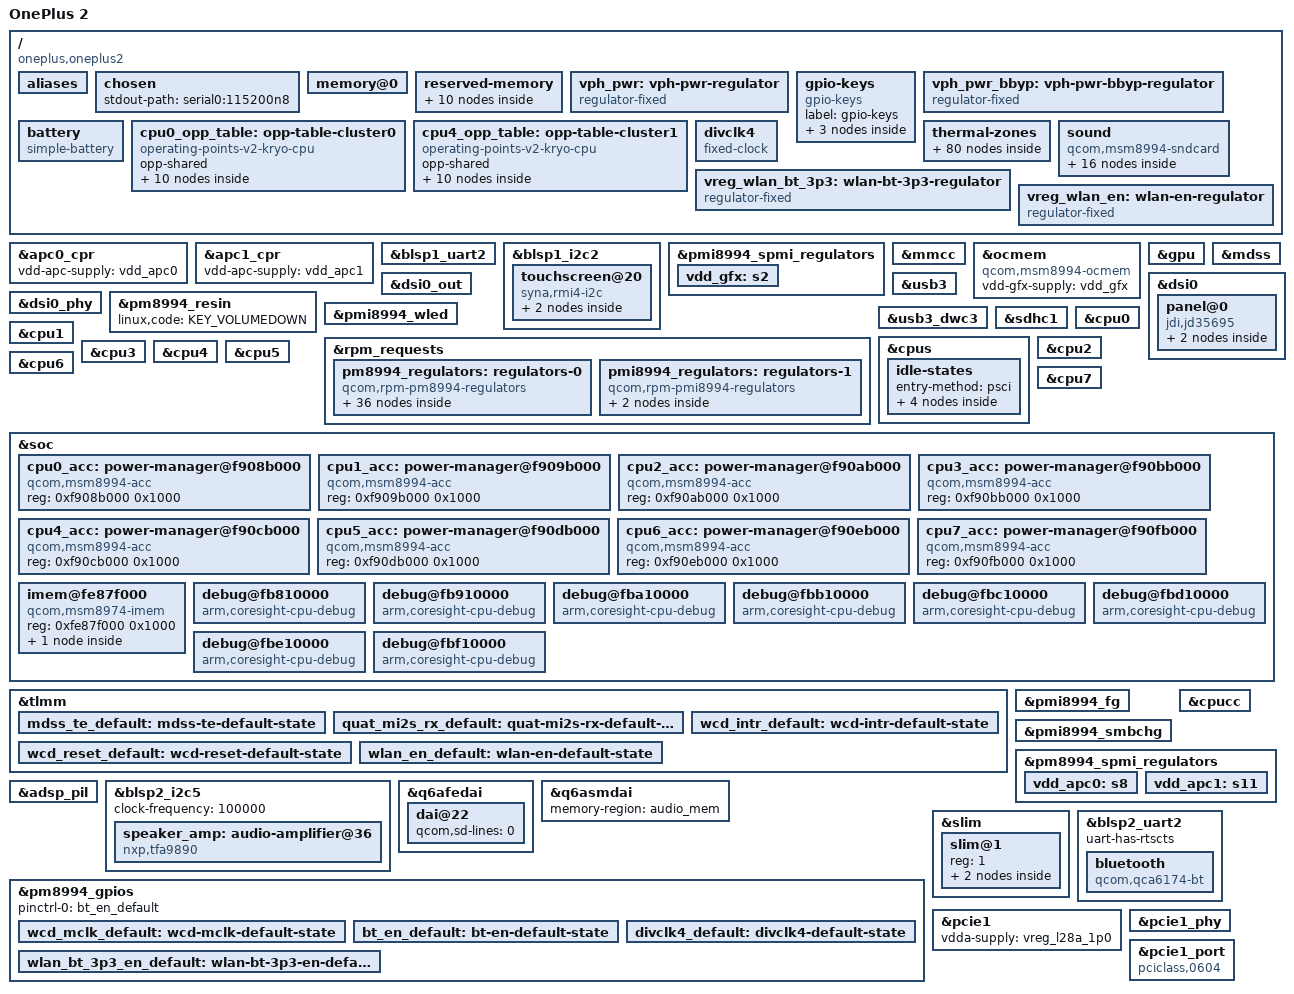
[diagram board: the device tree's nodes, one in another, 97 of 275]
// SPDX-License-Identifier: BSD-3-Clause
/*
 * OnePlus 2 (oneplus2, project 14049), MSM8994 v2.1.
 *
 * The memory map, regulator voltages and peripherals follow the stock
 * OxygenOS 3.10 device tree (board-id 14) and what the stock kernel logs on
 * the phone.
 */

/dts-v1/;

#include "msm8994.dtsi"
#include "pm8994.dtsi"
#include "pmi8994.dtsi"
#include <dt-bindings/gpio/gpio.h>
#include <dt-bindings/input/gpio-keys.h>
#include <dt-bindings/input/input.h>
#include <dt-bindings/interrupt-controller/irq.h>
#include <dt-bindings/pinctrl/qcom,pmic-gpio.h>
#include <dt-bindings/thermal/thermal.h>

/* placed as the stock kernel places them */
/delete-node/ &audio_mem;
/delete-node/ &adsp_mem;

/ {
	model = "OnePlus 2";
	compatible = "oneplus,oneplus2", "qcom,msm8994";
	chassis-type = "handset";

	/* the stock LK picks its DTB by these */
	qcom,msm-id = <207 0x20001>;
	qcom,board-id = <8 0 14049 14>;

	aliases {
		serial0 = &blsp1_uart2;
		serial1 = &blsp2_uart2;
		mmc0 = &sdhc1;
	};

	chosen {
		stdout-path = "serial0:115200n8";
	};

	/* LK rewrites the banks from SMEM; these are the 4 GB phone's */
	memory@0 {
		device_type = "memory";
		reg = <0 0x00000000 0 0x80000000>,
		      <0 0x80000000 0 0x78000000>;
	};

	reserved-memory {
		/*
		 * The TZ has no PSCI: lk2nd starts the secondary CPUs and parks
		 * them here (spin-table), in RAM no bootloader loads into.
		 */
		spin-table@6100000 {
			reg = <0 0x06100000 0 0x1000>;
			no-map;
		};

		nvbackup_mem: memory@6200000 {
			reg = <0 0x06200000 0 0x100000>;
			no-map;
		};

		/* holds SMEM (0x6a00000) and the hypervisor (0x6c00000) */
		memory_hole: memory@6300000 {
			reg = <0 0x06300000 0 0x700000>;
			no-map;
		};

		tzapp_mem: memory@e900000 {
			reg = <0 0x0e900000 0 0x1900000>;
			no-map;
		};

		/* the layout the OnePlus 2 kernels and TWRP use, so each reads the other */
		ramoops@ac000000 {
			compatible = "ramoops";
			reg = <0 0xac000000 0 0x100000>;
			record-size = <0x1000>;
			console-size = <0x40000>;
			ftrace-size = <0x1000>;
			pmsg-size = <0x1000>;
		};

		param_mem: memory@ac200000 {
			reg = <0 0xac200000 0 0x100000>;
			no-map;
		};

		mtp_mem: memory@ac400000 {
			reg = <0 0xac400000 0 0x100000>;
			no-map;
		};

		/* the ADSP's audio buffers (q6asm), shared with it through the TZ */
		audio_mem: memory@df400000 {
			compatible = "shared-dma-pool";
			reg = <0 0xdf400000 0 0x800000>;
			no-map;
		};

		qseecom_mem: memory@dfc00000 {
			reg = <0 0xdfc00000 0 0x1800000>;
			no-map;
		};

		adsp_mem: memory@e1400000 {
			reg = <0 0xe1400000 0 0x3f00000>;
			no-map;
		};
	};

	vph_pwr: vph-pwr-regulator {
		compatible = "regulator-fixed";
		regulator-name = "vph_pwr";
		regulator-min-microvolt = <3700000>;
		regulator-max-microvolt = <3700000>;
		regulator-always-on;
		regulator-boot-on;
	};

	gpio-keys {
		compatible = "gpio-keys";
		label = "gpio-keys";

		key-volume-up {
			label = "volume_up";
			gpios = <&pm8994_gpios 3 GPIO_ACTIVE_LOW>;
			linux,input-type = <EV_KEY>;
			linux,code = <KEY_VOLUMEUP>;
			debounce-interval = <15>;
		};

		key-volume-down {
			label = "volume_down";
			gpios = <&pm8994_gpios 2 GPIO_ACTIVE_LOW>;
			linux,input-type = <EV_KEY>;
			linux,code = <KEY_VOLUMEDOWN>;
			debounce-interval = <15>;
		};

		event-hall-sensor {
			label = "hall_sensor";
			gpios = <&tlmm 75 GPIO_ACTIVE_LOW>;
			linux,input-type = <EV_SW>;
			linux,code = <SW_LID>;
			debounce-interval = <15>;
			wakeup-source;
		};
	};

	vph_pwr_bbyp: vph-pwr-bbyp-regulator {
		compatible = "regulator-fixed";
		regulator-name = "vph_pwr_bbyp";
		regulator-min-microvolt = <3700000>;
		regulator-max-microvolt = <3700000>;
		regulator-always-on;
		regulator-boot-on;
	};
};

&apc0_cpr {
	vdd-apc-supply = <&vdd_apc0>;
	status = "okay";
};

&apc1_cpr {
	vdd-apc-supply = <&vdd_apc1>;
	status = "okay";
};

&blsp1_uart2 {
	status = "okay";
};

&blsp1_i2c2 {
	status = "okay";

	/* Synaptics S3320, RMI4 */
	touchscreen@20 {
		compatible = "syna,rmi4-i2c";
		reg = <0x20>;
		#address-cells = <1>;
		#size-cells = <0>;

		interrupts-extended = <&tlmm 96 IRQ_TYPE_LEVEL_LOW>;
		reset-gpios = <&tlmm 31 GPIO_ACTIVE_LOW>;
		vdd-supply = <&vreg_l22a_3p0>;

		syna,startup-delay-ms = <100>;

		rmi4-f01@1 {
			reg = <0x01>;
			syna,nosleep-mode = <2>;	/* on: no doze, quick taps register */
		};

		rmi4-f12@12 {
			reg = <0x12>;
			syna,sensor-type = <1>;
		};
	};
};

&pmi8994_spmi_regulators {
	/*
	 * S2 (ganged with S3) is VDD_GFX, the GX GDSC's parent supply in the
	 * stock device tree (pmi8994_s2_corner).  Without it the GPU's GX
	 * clocks never turn on and its IOMMU hangs the bus at probe.
	 */
	vdd_gfx: s2 {
		regulator-min-microvolt = <980000>;
		regulator-max-microvolt = <980000>;
	};
};

&mmcc {
	vdd-gfx-supply = <&vdd_gfx>;
	/*
	 * The MMSS clocks and PLLs run on VDDCX: the stock clock driver
	 * votes CX corners for them (vdd_dig-supply = pm8994_s1_corner).
	 * Without a vote MMPLL1 can fail to lock and MDP probe hangs.
	 */
	power-domains = <&rpmpd MSM8994_VDDCX>;
	required-opps = <&rpmpd_opp_nom>;
};

&ocmem {
	compatible = "qcom,msm8994-ocmem";
	vdd-gfx-supply = <&vdd_gfx>;
};

&gpu {
	status = "okay";
};

&mdss {
	status = "okay";
};

&dsi0 {
	#address-cells = <1>;
	#size-cells = <0>;

	vdda-supply = <&vreg_l2a_1p25>;
	vddio-supply = <&vreg_l14a_1p8>;
	status = "okay";

	panel@0 {
		compatible = "jdi,jd35695";
		reg = <0>;

		backlight = <&pmi8994_wled>;
		vddio-supply = <&vreg_l14a_1p8>;
		reset-gpios = <&tlmm 78 GPIO_ACTIVE_LOW>;

		pinctrl-0 = <&mdss_te_default>;
		pinctrl-names = "default";

		port {
			panel_in: endpoint {
				remote-endpoint = <&dsi0_out>;
			};
		};
	};
};

&dsi0_out {
	remote-endpoint = <&panel_in>;
	data-lanes = <0 1 2 3>;
};

&dsi0_phy {
	/* The stock panel timings: without them the last line is lost */
	qcom,t-clk-post = <0x20>;
	qcom,t-clk-pre = <0x3e>;
	status = "okay";
};

&pm8994_resin {
	linux,code = <KEY_VOLUMEDOWN>;
	status = "okay";
};

&pmi8994_wled {
	qcom,enabled-strings = <0 1>;
	qcom,current-limit-microamp = <20000>;
	qcom,ovp-millivolt = <29500>;
	qcom,switching-freq = <800>;
	qcom,cabc;
	status = "okay";
};

&rpm_requests {
	pm8994_regulators: regulators-0 {
		compatible = "qcom,rpm-pm8994-regulators";

		vdd_s1-supply = <&vph_pwr>;
		vdd_s2-supply = <&vph_pwr>;
		vdd_s3-supply = <&vph_pwr>;
		vdd_s4-supply = <&vph_pwr>;
		vdd_s5-supply = <&vph_pwr>;
		vdd_s6-supply = <&vph_pwr>;
		vdd_s7-supply = <&vph_pwr>;
		vdd_s8-supply = <&vph_pwr>;
		vdd_s9-supply = <&vph_pwr>;
		vdd_s10-supply = <&vph_pwr>;
		vdd_s11-supply = <&vph_pwr>;
		vdd_s12-supply = <&vph_pwr>;
		vdd_l1-supply = <&vreg_s1b_1p025>;
		vdd_l2_l26_l28-supply = <&vreg_s3a_1p3>;
		vdd_l3_l11-supply = <&vreg_s3a_1p3>;
		vdd_l4_l27_l31-supply = <&vreg_s3a_1p3>;
		vdd_l5_l7-supply = <&vreg_s5a_2p15>;
		vdd_l6_l12_l32-supply = <&vreg_s5a_2p15>;
		vdd_l8_l16_l30-supply = <&vph_pwr>;
		vdd_l9_l10_l18_l22-supply = <&vph_pwr_bbyp>;
		vdd_l13_l19_l23_l24-supply = <&vph_pwr_bbyp>;
		vdd_l14_l15-supply = <&vreg_s5a_2p15>;
		vdd_l17_l29-supply = <&vph_pwr_bbyp>;
		vdd_l20_l21-supply = <&vph_pwr_bbyp>;
		vdd_l25-supply = <&vreg_s5a_2p15>;
		vdd_lvs1_2-supply = <&vreg_s4a_1p8>;

		/* S1, S2, S6 and S12 are RPMPD's; S8-S11 the CPUs' (SPMI) */

		vreg_s3a_1p3: s3 {
			regulator-min-microvolt = <1300000>;
			regulator-max-microvolt = <1300000>;
		};

		vreg_s4a_1p8: s4 {
			regulator-min-microvolt = <1800000>;
			regulator-max-microvolt = <1800000>;
			regulator-always-on;
			regulator-allow-set-load;
			regulator-system-load = <325000>;
		};

		vreg_s5a_2p15: s5 {
			regulator-min-microvolt = <2150000>;
			regulator-max-microvolt = <2150000>;
		};

		vreg_s7a_1p0: s7 {
			regulator-min-microvolt = <1000000>;
			regulator-max-microvolt = <1000000>;
		};

		vreg_l1a_1p0: l1 {
			regulator-min-microvolt = <1000000>;
			regulator-max-microvolt = <1000000>;
		};

		vreg_l2a_1p25: l2 {
			regulator-min-microvolt = <1250000>;
			regulator-max-microvolt = <1250000>;
		};

		vreg_l3a_1p25: l3 {
			regulator-min-microvolt = <1250000>;
			regulator-max-microvolt = <1250000>;
		};

		vreg_l4a_1p225: l4 {
			regulator-min-microvolt = <1225000>;
			regulator-max-microvolt = <1225000>;
		};

		vreg_l6a_1p8: l6 {
			regulator-min-microvolt = <1800000>;
			regulator-max-microvolt = <1800000>;
			/*
			 * USB HS PHY vdda18: no PHY driver claims it yet.  Its load
			 * (vendor: 19 mA) keeps the LDO out of low power mode.
			 */
			regulator-always-on;
			regulator-allow-set-load;
			regulator-system-load = <19000>;
		};

		vreg_l8a_1p8: l8 {
			regulator-min-microvolt = <1800000>;
			regulator-max-microvolt = <1800000>;
		};

		vreg_l9a_1p8: l9 {
			regulator-min-microvolt = <1800000>;
			regulator-max-microvolt = <1800000>;
		};

		vreg_l10a_1p8: l10 {
			regulator-min-microvolt = <1800000>;
			regulator-max-microvolt = <1800000>;
		};

		vreg_l11a_1p2: l11 {
			regulator-min-microvolt = <1200000>;
			regulator-max-microvolt = <1200000>;
		};

		vreg_l12a_1p8: l12 {
			regulator-min-microvolt = <1800000>;
			regulator-max-microvolt = <1800000>;
			/* MMPLL analog supply (stock mmpll4_analog-supply) */
			regulator-always-on;
		};

		vreg_l13a_2p95: l13 {
			regulator-min-microvolt = <1800000>;
			regulator-max-microvolt = <2950000>;
		};

		vreg_l14a_1p8: l14 {
			regulator-min-microvolt = <1800000>;
			regulator-max-microvolt = <1800000>;
		};

		vreg_l15a_1p8: l15 {
			regulator-min-microvolt = <1800000>;
			regulator-max-microvolt = <1800000>;
		};

		vreg_l16a_2p7: l16 {
			regulator-min-microvolt = <2700000>;
			regulator-max-microvolt = <2700000>;
			regulator-always-on;
		};

		vreg_l17a_2p7: l17 {
			regulator-min-microvolt = <2700000>;
			regulator-max-microvolt = <2700000>;
		};

		vreg_l18a_2p85: l18 {
			regulator-min-microvolt = <2850000>;
			regulator-max-microvolt = <2850000>;
		};

		vreg_l19a_2p8: l19 {
			regulator-min-microvolt = <2800000>;
			regulator-max-microvolt = <2800000>;
		};

		vreg_l20a_2p95: l20 {
			regulator-min-microvolt = <2950000>;
			regulator-max-microvolt = <2950000>;
			regulator-allow-set-load;
			regulator-system-load = <570000>;
		};

		vreg_l21a_2p95: l21 {
			regulator-min-microvolt = <2950000>;
			regulator-max-microvolt = <2950000>;
			regulator-always-on;
		};

		vreg_l22a_3p0: l22 {
			regulator-min-microvolt = <3000000>;
			regulator-max-microvolt = <3000000>;
		};

		vreg_l23a_2p8: l23 {
			regulator-min-microvolt = <2800000>;
			regulator-max-microvolt = <2800000>;
		};

		vreg_l24a_3p075: l24 {
			regulator-min-microvolt = <3075000>;
			regulator-max-microvolt = <3150000>;
			/* USB HS PHY vdda33, as l6 (vendor load: 16 mA) */
			regulator-always-on;
			regulator-allow-set-load;
			regulator-system-load = <16000>;
		};

		vreg_l25a_1p0: l25 {
			regulator-min-microvolt = <1000000>;
			regulator-max-microvolt = <1000000>;
		};

		vreg_l26a_0p9875: l26 {
			regulator-min-microvolt = <987500>;
			regulator-max-microvolt = <987500>;
		};

		vreg_l27a_1p05: l27 {
			regulator-min-microvolt = <1050000>;
			regulator-max-microvolt = <1050000>;
		};

		vreg_l28a_1p0: l28 {
			regulator-min-microvolt = <1000000>;
			regulator-max-microvolt = <1000000>;
			regulator-allow-set-load;
			regulator-system-load = <40000>;
		};

		vreg_l29a_2p8: l29 {
			regulator-min-microvolt = <2800000>;
			regulator-max-microvolt = <2800000>;
		};

		vreg_l30a_1p8: l30 {
			regulator-min-microvolt = <1800000>;
			regulator-max-microvolt = <1800000>;
			regulator-always-on;
		};

		vreg_l31a_1p2: l31 {
			regulator-min-microvolt = <1200000>;
			regulator-max-microvolt = <1200000>;
		};

		vreg_l32a_1p8: l32 {
			regulator-min-microvolt = <1800000>;
			regulator-max-microvolt = <1800000>;
		};

		vreg_lvs1a_1p8: lvs1 {};
		vreg_lvs2a_1p8: lvs2 {};
	};

	pmi8994_regulators: regulators-1 {
		compatible = "qcom,rpm-pmi8994-regulators";

		vdd_s1-supply = <&vph_pwr>;
		vdd_s2-supply = <&vph_pwr>;
		vdd_s3-supply = <&vph_pwr>;
		vdd_bst_byp-supply = <&vph_pwr>;

		vreg_s1b_1p025: s1 {
			regulator-min-microvolt = <1025000>;
			regulator-max-microvolt = <1025000>;
		};

		vreg_bst_byp: boost-bypass {
			regulator-min-microvolt = <3150000>;
			regulator-max-microvolt = <3600000>;
		};
	};
};

&usb3 {
	/* QSCRATCH, the HS PHY CSRs (USB2PHY), and TCSR_USB30_CONTROL */
	reg = <0xf92f8800 0x400>,
	      <0xf9b3a000 0x110>,
	      <0xfd4ab000 0x4>;
	reg-names = "qscratch", "phy_csr", "tcsr";

	/* HS PHY tuning, as the stock device tree sets it */
	qcom,hsphy-init = <0xd187a7>;
	qcom,set-pllbtune;

	/* The vendor glue resets the core and the HS PHY before setting it up */
	resets = <&gcc USB_30_RESET>, <&gcc USB2_HS_PHY_ONLY_RESET>;

	/*
	 * Also the HS PHY clocks, which the vendor PHY driver held: no
	 * mainline driver claims them and they would be turned off as unused.
	 */
	clocks = <&gcc GCC_USB30_MASTER_CLK>,
		 <&gcc GCC_SYS_NOC_USB3_AXI_CLK>,
		 <&gcc GCC_USB30_SLEEP_CLK>,
		 <&gcc GCC_USB30_MOCK_UTMI_CLK>,
		 <&gcc GCC_USB2_HS_PHY_SLEEP_CLK>,
		 <&gcc GCC_USB_PHY_CFG_AHB2PHY_CLK>;
	clock-names = "core",
		      "iface",
		      "sleep",
		      "mock_utmi",
		      "phy_sleep",
		      "phy_cfg_ahb";
	status = "okay";
};

&usb3_dwc3 {
	dr_mode = "peripheral";
	maximum-speed = "high-speed";
	/* Qualcomm: the RAM clock gets stuck in low power with gating on */
	snps,dis_clk_gating_quirk;
};

&sdhc1 {
	vmmc-supply = <&vreg_l20a_2p95>;
	vqmmc-supply = <&vreg_s4a_1p8>;
	non-removable;
	bus-width = <8>;
	status = "okay";
};

&cpus {
	idle-states {
		entry-method = "psci";

		little_cpu_ret: cpu-retention-0 {
			compatible = "arm,idle-state";
			idle-state-name = "little-retention";
			arm,psci-suspend-param = <0x00000001>;
			entry-latency-us = <40>;
			exit-latency-us = <100>;
			min-residency-us = <300>;
			local-timer-stop;
		};

		little_cpu_pc: cpu-power-collapse-0 {
			compatible = "arm,idle-state";
			idle-state-name = "little-power-collapse";
			arm,psci-suspend-param = <0x00010003>;
			entry-latency-us = <300>;
			exit-latency-us = <480>;
			min-residency-us = <2000>;
			local-timer-stop;
		};

		big_cpu_ret: cpu-retention-1 {
			compatible = "arm,idle-state";
			idle-state-name = "big-retention";
			arm,psci-suspend-param = <0x00000001>;
			entry-latency-us = <40>;
			exit-latency-us = <120>;
			min-residency-us = <400>;
			local-timer-stop;
		};

		big_cpu_pc: cpu-power-collapse-1 {
			compatible = "arm,idle-state";
			idle-state-name = "big-power-collapse";
			arm,psci-suspend-param = <0x00010003>;
			entry-latency-us = <300>;
			exit-latency-us = <640>;
			min-residency-us = <3000>;
			local-timer-stop;
		};
	};
};

/* Per-CPU ACC (power control) that lk2nd uses to start the cores */
&cpu0 {
	qcom,acc = <&cpu0_acc>;
	cpu-idle-states = <&little_cpu_ret &little_cpu_pc>;
};

&cpu1 {
	qcom,acc = <&cpu1_acc>;
	cpu-idle-states = <&little_cpu_ret &little_cpu_pc>;
};

&cpu2 {
	qcom,acc = <&cpu2_acc>;
	cpu-idle-states = <&little_cpu_ret &little_cpu_pc>;
};

&cpu3 {
	qcom,acc = <&cpu3_acc>;
	cpu-idle-states = <&little_cpu_ret &little_cpu_pc>;
};

&cpu4 {
	qcom,acc = <&cpu4_acc>;
	cpu-idle-states = <&big_cpu_ret &big_cpu_pc>;
};

&cpu5 {
	qcom,acc = <&cpu5_acc>;
	cpu-idle-states = <&big_cpu_ret &big_cpu_pc>;
};

&cpu6 {
	qcom,acc = <&cpu6_acc>;
	cpu-idle-states = <&big_cpu_ret &big_cpu_pc>;
};

&cpu7 {
	qcom,acc = <&cpu7_acc>;
	cpu-idle-states = <&big_cpu_ret &big_cpu_pc>;
};

&soc {
	cpu0_acc: power-manager@f908b000 {
		compatible = "qcom,msm8994-acc";
		reg = <0xf908b000 0x1000>;
	};

	cpu1_acc: power-manager@f909b000 {
		compatible = "qcom,msm8994-acc";
		reg = <0xf909b000 0x1000>;
	};

	cpu2_acc: power-manager@f90ab000 {
		compatible = "qcom,msm8994-acc";
		reg = <0xf90ab000 0x1000>;
	};

	cpu3_acc: power-manager@f90bb000 {
		compatible = "qcom,msm8994-acc";
		reg = <0xf90bb000 0x1000>;
	};

	cpu4_acc: power-manager@f90cb000 {
		compatible = "qcom,msm8994-acc";
		reg = <0xf90cb000 0x1000>;
	};

	cpu5_acc: power-manager@f90db000 {
		compatible = "qcom,msm8994-acc";
		reg = <0xf90db000 0x1000>;
	};

	cpu6_acc: power-manager@f90eb000 {
		compatible = "qcom,msm8994-acc";
		reg = <0xf90eb000 0x1000>;
	};

	cpu7_acc: power-manager@f90fb000 {
		compatible = "qcom,msm8994-acc";
		reg = <0xf90fb000 0x1000>;
	};
};

&soc {
	/* LK reads the restart reason here: fastboot and recovery */
	imem@fe87f000 {
		compatible = "qcom,msm8974-imem", "syscon", "simple-mfd";
		reg = <0xfe87f000 0x1000>;

		reboot-mode {
			compatible = "syscon-reboot-mode";
			offset = <0x65c>;
			mode-bootloader = <0x77665500>;
			mode-recovery = <0x77665502>;
		};
	};
};

&soc {
	/*
	 * CPU external debug (EDPCSR): the PCs of stuck cores on panic.
	 * Only cores lk2nd starts: the debug block of a core that is
	 * powered down does not answer.
	 */
	debug@fb810000 {
		compatible = "arm,coresight-cpu-debug", "arm,primecell";
		reg = <0xfb810000 0x1000>;
		clocks = <&rpmcc RPM_SMD_QDSS_CLK>;
		clock-names = "apb_pclk";
		cpu = <&cpu0>;
	};

	debug@fb910000 {
		compatible = "arm,coresight-cpu-debug", "arm,primecell";
		reg = <0xfb910000 0x1000>;
		clocks = <&rpmcc RPM_SMD_QDSS_CLK>;
		clock-names = "apb_pclk";
		cpu = <&cpu1>;
	};

	debug@fba10000 {
		compatible = "arm,coresight-cpu-debug", "arm,primecell";
		reg = <0xfba10000 0x1000>;
		clocks = <&rpmcc RPM_SMD_QDSS_CLK>;
		clock-names = "apb_pclk";
		cpu = <&cpu2>;
	};

	debug@fbb10000 {
		compatible = "arm,coresight-cpu-debug", "arm,primecell";
		reg = <0xfbb10000 0x1000>;
		clocks = <&rpmcc RPM_SMD_QDSS_CLK>;
		clock-names = "apb_pclk";
		cpu = <&cpu3>;
	};

	debug@fbc10000 {
		compatible = "arm,coresight-cpu-debug", "arm,primecell";
		reg = <0xfbc10000 0x1000>;
		clocks = <&rpmcc RPM_SMD_QDSS_CLK>;
		clock-names = "apb_pclk";
		cpu = <&cpu4>;
	};

	debug@fbd10000 {
		compatible = "arm,coresight-cpu-debug", "arm,primecell";
		reg = <0xfbd10000 0x1000>;
		clocks = <&rpmcc RPM_SMD_QDSS_CLK>;
		clock-names = "apb_pclk";
		cpu = <&cpu5>;
	};

	debug@fbe10000 {
		compatible = "arm,coresight-cpu-debug", "arm,primecell";
		reg = <0xfbe10000 0x1000>;
		clocks = <&rpmcc RPM_SMD_QDSS_CLK>;
		clock-names = "apb_pclk";
		cpu = <&cpu6>;
	};

	debug@fbf10000 {
		compatible = "arm,coresight-cpu-debug", "arm,primecell";
		reg = <0xfbf10000 0x1000>;
		clocks = <&rpmcc RPM_SMD_QDSS_CLK>;
		clock-names = "apb_pclk";
		cpu = <&cpu7>;
	};
};

&tlmm {
	/* The panel's tearing effect output: MDP starts its transfers on it */
	mdss_te_default: mdss-te-default-state {
		pins = "gpio10";
		function = "mdp_vsync";
		drive-strength = <2>;
		bias-pull-down;
	};
};

/ {
	/* 3300 mAh, 4.32 V (stock batterydata_oneplus_{ATL,SDI}_3300mAh) */
	battery: battery {
		compatible = "simple-battery";
		device-chemistry = "lithium-ion-polymer";
		charge-full-design-microamp-hours = <3300000>;
		voltage-max-design-microvolt = <4320000>;
		constant-charge-voltage-max-microvolt = <4320000>;
		constant-charge-current-max-microamp = <1910000>;
		charge-term-current-microamp = <150000>;
	};
};

&pmi8994_fg {
	/*
	 * Read only for now: no tuning values and no profile, so the gauge
	 * keeps what the vendor firmware left in it.  The ID range is only
	 * there to have the battery ID resistor measured and logged.
	 */
	monitored-battery = <&battery>;
	/* ATL 3300 mAh (the SDI cell reads 50 kOhm and shows as unknown) */
	qcom,battery-type = "ATL";
	qcom,batt-id-kohm = <1>;
	/* the ID reads in whole kOhm: accept 0..2 */
	qcom,batt-id-range-pct = <100>;
	status = "okay";
};

&pmi8994_smbchg {
	monitored-battery = <&battery>;

	/*
	 * The vendor kernel's charging zones (qpnp-smbcharger.c): up to this
	 * battery temperature (0.1 degC), float voltage (uV) and charge
	 * current (uA).  No charging below the first and above the last.
	 */
	qcom,temp-zones = <(-30)       0       0>,
			  <   0  3980000  300000>,
			  <  50  4320000  500000>,
			  < 120  4320000  800000>,
			  < 220  4320000 1300000>,
			  < 450  4320000 1910000>,
			  < 550  4080000  600000>;
	qcom,temp-hysteresis = <20>;

	status = "okay";
};

&cpucc {
	/*
	 * The CPU rails above 1.0 V need VDD_MX at its top corner
	 * (stock qcom,vdd-mx-corner-map of the CPR regulators).
	 */
	power-domains = <&rpmpd MSM8994_VDDMX>;
	required-opps = <&rpmpd_opp_super_turbo>;
};

/*
 * CPU frequency scaling.  Frequencies are the stock v2 tables
 * (qcom,a53/a57-speedbin0-v0); CPR sets the voltage of each step.
 * The top stock steps (Cortex-A57 above 1536 MHz, 1.225 V) are left out:
 * the SoC idles around 60 C and resets itself at 115 C.
 */
/ {
	cpu0_opp_table: opp-table-cluster0 {
		compatible = "operating-points-v2-kryo-cpu";
		opp-shared;

		opp-384000000 {
			opp-hz = /bits/ 64 <384000000>;
			required-opps = <&apc0_cpr_opp1>;
			clock-latency-ns = <300000>;
		};
		opp-460800000 {
			opp-hz = /bits/ 64 <460800000>;
			required-opps = <&apc0_cpr_opp2>;
			clock-latency-ns = <300000>;
		};
		opp-672000000 {
			opp-hz = /bits/ 64 <672000000>;
			required-opps = <&apc0_cpr_opp3>;
			clock-latency-ns = <300000>;
		};
		opp-768000000 {
			opp-hz = /bits/ 64 <768000000>;
			required-opps = <&apc0_cpr_opp4>;
			clock-latency-ns = <300000>;
		};
		opp-864000000 {
			opp-hz = /bits/ 64 <864000000>;
			required-opps = <&apc0_cpr_opp5>;
			clock-latency-ns = <300000>;
		};
		opp-960000000 {
			opp-hz = /bits/ 64 <960000000>;
			required-opps = <&apc0_cpr_opp6>;
			clock-latency-ns = <300000>;
		};
		opp-1248000000 {
			opp-hz = /bits/ 64 <1248000000>;
			required-opps = <&apc0_cpr_opp7>;
			clock-latency-ns = <300000>;
		};
		opp-1344000000 {
			opp-hz = /bits/ 64 <1344000000>;
			required-opps = <&apc0_cpr_opp8>;
			clock-latency-ns = <300000>;
		};
		opp-1478400000 {
			opp-hz = /bits/ 64 <1478400000>;
			required-opps = <&apc0_cpr_opp9>;
			clock-latency-ns = <300000>;
		};
		opp-1555200000 {
			opp-hz = /bits/ 64 <1555200000>;
			required-opps = <&apc0_cpr_opp10>;
			clock-latency-ns = <300000>;
		};
	};

	cpu4_opp_table: opp-table-cluster1 {
		compatible = "operating-points-v2-kryo-cpu";
		opp-shared;

		opp-384000000 {
			opp-hz = /bits/ 64 <384000000>;
			required-opps = <&apc1_cpr_opp1>;
			clock-latency-ns = <300000>;
		};
		opp-480000000 {
			opp-hz = /bits/ 64 <480000000>;
			required-opps = <&apc1_cpr_opp2>;
			clock-latency-ns = <300000>;
		};
		opp-633600000 {
			opp-hz = /bits/ 64 <633600000>;
			required-opps = <&apc1_cpr_opp3>;
			clock-latency-ns = <300000>;
		};
		opp-768000000 {
			opp-hz = /bits/ 64 <768000000>;
			required-opps = <&apc1_cpr_opp4>;
			clock-latency-ns = <300000>;
		};
		opp-864000000 {
			opp-hz = /bits/ 64 <864000000>;
			required-opps = <&apc1_cpr_opp5>;
			clock-latency-ns = <300000>;
		};
		opp-960000000 {
			opp-hz = /bits/ 64 <960000000>;
			required-opps = <&apc1_cpr_opp6>;
			clock-latency-ns = <300000>;
		};
		opp-1248000000 {
			opp-hz = /bits/ 64 <1248000000>;
			required-opps = <&apc1_cpr_opp7>;
			clock-latency-ns = <300000>;
		};
		opp-1344000000 {
			opp-hz = /bits/ 64 <1344000000>;
			required-opps = <&apc1_cpr_opp8>;
			clock-latency-ns = <300000>;
		};
		opp-1440000000 {
			opp-hz = /bits/ 64 <1440000000>;
			required-opps = <&apc1_cpr_opp9>;
			clock-latency-ns = <300000>;
		};
		opp-1536000000 {
			opp-hz = /bits/ 64 <1536000000>;
			required-opps = <&apc1_cpr_opp10>;
			clock-latency-ns = <300000>;
		};
	};
};

&pm8994_spmi_regulators {
	/* VDD_APC0: Cortex-A53 cluster and CCI */
	vdd_apc0: s8 {
		regulator-min-microvolt = <1000000>;
		regulator-max-microvolt = <1180000>;
		regulator-always-on;
		regulator-boot-on;
	};

	/* VDD_APC1: Cortex-A57 cluster, S11 leads S9 and S10 */
	vdd_apc1: s11 {
		regulator-min-microvolt = <700000>;
		regulator-max-microvolt = <1225000>;
		regulator-always-on;
		regulator-boot-on;
	};
};

&cpu0 {
	#cooling-cells = <2>;
	operating-points-v2 = <&cpu0_opp_table>;
	power-domains = <&apc0_cpr>;
	power-domain-names = "cpr";
};

&cpu1 {
	#cooling-cells = <2>;
	operating-points-v2 = <&cpu0_opp_table>;
	power-domains = <&apc0_cpr>;
	power-domain-names = "cpr";
};

&cpu2 {
	#cooling-cells = <2>;
	operating-points-v2 = <&cpu0_opp_table>;
	power-domains = <&apc0_cpr>;
	power-domain-names = "cpr";
};

&cpu3 {
	#cooling-cells = <2>;
	operating-points-v2 = <&cpu0_opp_table>;
	power-domains = <&apc0_cpr>;
	power-domain-names = "cpr";
};

&cpu4 {
	#cooling-cells = <2>;
	operating-points-v2 = <&cpu4_opp_table>;
	power-domains = <&apc1_cpr>;
	power-domain-names = "cpr";
};

&cpu5 {
	#cooling-cells = <2>;
	operating-points-v2 = <&cpu4_opp_table>;
	power-domains = <&apc1_cpr>;
	power-domain-names = "cpr";
};

&cpu6 {
	#cooling-cells = <2>;
	operating-points-v2 = <&cpu4_opp_table>;
	power-domains = <&apc1_cpr>;
	power-domain-names = "cpr";
};

&cpu7 {
	#cooling-cells = <2>;
	operating-points-v2 = <&cpu4_opp_table>;
	power-domains = <&apc1_cpr>;
	power-domain-names = "cpr";
};

/*
 * The SoC already reaches the mid 90s C during boot at 768 MHz and resets
 * itself at 115 C, so each cluster is limited in narrow bands from the
 * sensor next to each of its cores: from 80 C down to 1248 MHz, from 90 C
 * to 864 or 768 MHz (the rate the boot firmware leaves), from 100 C down
 * to the lowest step.
 */
/ {
	thermal-zones {
		cpu0-thermal {
			polling-delay-passive = <100>;
			polling-delay = <0>;
			thermal-sensors = <&tsens 7>;

			trips {
				cpu0_alert0: trip-point0 {
					temperature = <80000>;
					hysteresis = <2000>;
					type = "passive";
				};

				cpu0_alert1: trip-point1 {
					temperature = <90000>;
					hysteresis = <2000>;
					type = "passive";
				};

				cpu0_alert2: trip-point2 {
					temperature = <100000>;
					hysteresis = <2000>;
					type = "passive";
				};

				cpu0-crit {
					temperature = <110000>;
					hysteresis = <2000>;
					type = "critical";
				};
			};

			cooling-maps {
				map0 {
					trip = <&cpu0_alert0>;
					cooling-device = <&cpu0 THERMAL_NO_LIMIT 3>,
						 <&cpu1 THERMAL_NO_LIMIT 3>,
						 <&cpu2 THERMAL_NO_LIMIT 3>,
						 <&cpu3 THERMAL_NO_LIMIT 3>;
				};

				map1 {
					trip = <&cpu0_alert1>;
					cooling-device = <&cpu0 4 6>,
						 <&cpu1 4 6>,
						 <&cpu2 4 6>,
						 <&cpu3 4 6>;
				};

				map2 {
					trip = <&cpu0_alert2>;
					cooling-device = <&cpu0 7 THERMAL_NO_LIMIT>,
						 <&cpu1 7 THERMAL_NO_LIMIT>,
						 <&cpu2 7 THERMAL_NO_LIMIT>,
						 <&cpu3 7 THERMAL_NO_LIMIT>;
				};
			};
		};

		cpu1-thermal {
			polling-delay-passive = <100>;
			polling-delay = <0>;
			thermal-sensors = <&tsens 8>;

			trips {
				cpu1_alert0: trip-point0 {
					temperature = <80000>;
					hysteresis = <2000>;
					type = "passive";
				};

				cpu1_alert1: trip-point1 {
					temperature = <90000>;
					hysteresis = <2000>;
					type = "passive";
				};

				cpu1_alert2: trip-point2 {
					temperature = <100000>;
					hysteresis = <2000>;
					type = "passive";
				};

				cpu1-crit {
					temperature = <110000>;
					hysteresis = <2000>;
					type = "critical";
				};
			};

			cooling-maps {
				map0 {
					trip = <&cpu1_alert0>;
					cooling-device = <&cpu0 THERMAL_NO_LIMIT 3>,
						 <&cpu1 THERMAL_NO_LIMIT 3>,
						 <&cpu2 THERMAL_NO_LIMIT 3>,
						 <&cpu3 THERMAL_NO_LIMIT 3>;
				};

				map1 {
					trip = <&cpu1_alert1>;
					cooling-device = <&cpu0 4 6>,
						 <&cpu1 4 6>,
						 <&cpu2 4 6>,
						 <&cpu3 4 6>;
				};

				map2 {
					trip = <&cpu1_alert2>;
					cooling-device = <&cpu0 7 THERMAL_NO_LIMIT>,
						 <&cpu1 7 THERMAL_NO_LIMIT>,
						 <&cpu2 7 THERMAL_NO_LIMIT>,
						 <&cpu3 7 THERMAL_NO_LIMIT>;
				};
			};
		};

		cpu2-thermal {
			polling-delay-passive = <100>;
			polling-delay = <0>;
			thermal-sensors = <&tsens 9>;

			trips {
				cpu2_alert0: trip-point0 {
					temperature = <80000>;
					hysteresis = <2000>;
					type = "passive";
				};

				cpu2_alert1: trip-point1 {
					temperature = <90000>;
					hysteresis = <2000>;
					type = "passive";
				};

				cpu2_alert2: trip-point2 {
					temperature = <100000>;
					hysteresis = <2000>;
					type = "passive";
				};

				cpu2-crit {
					temperature = <110000>;
					hysteresis = <2000>;
					type = "critical";
				};
			};

			cooling-maps {
				map0 {
					trip = <&cpu2_alert0>;
					cooling-device = <&cpu0 THERMAL_NO_LIMIT 3>,
						 <&cpu1 THERMAL_NO_LIMIT 3>,
						 <&cpu2 THERMAL_NO_LIMIT 3>,
						 <&cpu3 THERMAL_NO_LIMIT 3>;
				};

				map1 {
					trip = <&cpu2_alert1>;
					cooling-device = <&cpu0 4 6>,
						 <&cpu1 4 6>,
						 <&cpu2 4 6>,
						 <&cpu3 4 6>;
				};

				map2 {
					trip = <&cpu2_alert2>;
					cooling-device = <&cpu0 7 THERMAL_NO_LIMIT>,
						 <&cpu1 7 THERMAL_NO_LIMIT>,
						 <&cpu2 7 THERMAL_NO_LIMIT>,
						 <&cpu3 7 THERMAL_NO_LIMIT>;
				};
			};
		};

		cpu3-thermal {
			polling-delay-passive = <100>;
			polling-delay = <0>;
			thermal-sensors = <&tsens 10>;

			trips {
				cpu3_alert0: trip-point0 {
					temperature = <80000>;
					hysteresis = <2000>;
					type = "passive";
				};

				cpu3_alert1: trip-point1 {
					temperature = <90000>;
					hysteresis = <2000>;
					type = "passive";
				};

				cpu3_alert2: trip-point2 {
					temperature = <100000>;
					hysteresis = <2000>;
					type = "passive";
				};

				cpu3-crit {
					temperature = <110000>;
					hysteresis = <2000>;
					type = "critical";
				};
			};

			cooling-maps {
				map0 {
					trip = <&cpu3_alert0>;
					cooling-device = <&cpu0 THERMAL_NO_LIMIT 3>,
						 <&cpu1 THERMAL_NO_LIMIT 3>,
						 <&cpu2 THERMAL_NO_LIMIT 3>,
						 <&cpu3 THERMAL_NO_LIMIT 3>;
				};

				map1 {
					trip = <&cpu3_alert1>;
					cooling-device = <&cpu0 4 6>,
						 <&cpu1 4 6>,
						 <&cpu2 4 6>,
						 <&cpu3 4 6>;
				};

				map2 {
					trip = <&cpu3_alert2>;
					cooling-device = <&cpu0 7 THERMAL_NO_LIMIT>,
						 <&cpu1 7 THERMAL_NO_LIMIT>,
						 <&cpu2 7 THERMAL_NO_LIMIT>,
						 <&cpu3 7 THERMAL_NO_LIMIT>;
				};
			};
		};

		cpu4-thermal {
			polling-delay-passive = <100>;
			polling-delay = <0>;
			thermal-sensors = <&tsens 13>;

			trips {
				cpu4_alert0: trip-point0 {
					temperature = <80000>;
					hysteresis = <2000>;
					type = "passive";
				};

				cpu4_alert1: trip-point1 {
					temperature = <90000>;
					hysteresis = <2000>;
					type = "passive";
				};

				cpu4_alert2: trip-point2 {
					temperature = <100000>;
					hysteresis = <2000>;
					type = "passive";
				};

				cpu4-crit {
					temperature = <110000>;
					hysteresis = <2000>;
					type = "critical";
				};
			};

			cooling-maps {
				map0 {
					trip = <&cpu4_alert0>;
					cooling-device = <&cpu4 THERMAL_NO_LIMIT 3>,
						 <&cpu5 THERMAL_NO_LIMIT 3>,
						 <&cpu6 THERMAL_NO_LIMIT 3>,
						 <&cpu7 THERMAL_NO_LIMIT 3>;
				};

				map1 {
					trip = <&cpu4_alert1>;
					cooling-device = <&cpu4 4 6>,
						 <&cpu5 4 6>,
						 <&cpu6 4 6>,
						 <&cpu7 4 6>;
				};

				map2 {
					trip = <&cpu4_alert2>;
					cooling-device = <&cpu4 7 THERMAL_NO_LIMIT>,
						 <&cpu5 7 THERMAL_NO_LIMIT>,
						 <&cpu6 7 THERMAL_NO_LIMIT>,
						 <&cpu7 7 THERMAL_NO_LIMIT>;
				};
			};
		};

		cpu5-thermal {
			polling-delay-passive = <100>;
			polling-delay = <0>;
			thermal-sensors = <&tsens 14>;

			trips {
				cpu5_alert0: trip-point0 {
					temperature = <80000>;
					hysteresis = <2000>;
					type = "passive";
				};

				cpu5_alert1: trip-point1 {
					temperature = <90000>;
					hysteresis = <2000>;
					type = "passive";
				};

				cpu5_alert2: trip-point2 {
					temperature = <100000>;
					hysteresis = <2000>;
					type = "passive";
				};

				cpu5-crit {
					temperature = <110000>;
					hysteresis = <2000>;
					type = "critical";
				};
			};

			cooling-maps {
				map0 {
					trip = <&cpu5_alert0>;
					cooling-device = <&cpu4 THERMAL_NO_LIMIT 3>,
						 <&cpu5 THERMAL_NO_LIMIT 3>,
						 <&cpu6 THERMAL_NO_LIMIT 3>,
						 <&cpu7 THERMAL_NO_LIMIT 3>;
				};

				map1 {
					trip = <&cpu5_alert1>;
					cooling-device = <&cpu4 4 6>,
						 <&cpu5 4 6>,
						 <&cpu6 4 6>,
						 <&cpu7 4 6>;
				};

				map2 {
					trip = <&cpu5_alert2>;
					cooling-device = <&cpu4 7 THERMAL_NO_LIMIT>,
						 <&cpu5 7 THERMAL_NO_LIMIT>,
						 <&cpu6 7 THERMAL_NO_LIMIT>,
						 <&cpu7 7 THERMAL_NO_LIMIT>;
				};
			};
		};

		cpu6-thermal {
			polling-delay-passive = <100>;
			polling-delay = <0>;
			thermal-sensors = <&tsens 15>;

			trips {
				cpu6_alert0: trip-point0 {
					temperature = <80000>;
					hysteresis = <2000>;
					type = "passive";
				};

				cpu6_alert1: trip-point1 {
					temperature = <90000>;
					hysteresis = <2000>;
					type = "passive";
				};

				cpu6_alert2: trip-point2 {
					temperature = <100000>;
					hysteresis = <2000>;
					type = "passive";
				};

				cpu6-crit {
					temperature = <110000>;
					hysteresis = <2000>;
					type = "critical";
				};
			};

			cooling-maps {
				map0 {
					trip = <&cpu6_alert0>;
					cooling-device = <&cpu4 THERMAL_NO_LIMIT 3>,
						 <&cpu5 THERMAL_NO_LIMIT 3>,
						 <&cpu6 THERMAL_NO_LIMIT 3>,
						 <&cpu7 THERMAL_NO_LIMIT 3>;
				};

				map1 {
					trip = <&cpu6_alert1>;
					cooling-device = <&cpu4 4 6>,
						 <&cpu5 4 6>,
						 <&cpu6 4 6>,
						 <&cpu7 4 6>;
				};

				map2 {
					trip = <&cpu6_alert2>;
					cooling-device = <&cpu4 7 THERMAL_NO_LIMIT>,
						 <&cpu5 7 THERMAL_NO_LIMIT>,
						 <&cpu6 7 THERMAL_NO_LIMIT>,
						 <&cpu7 7 THERMAL_NO_LIMIT>;
				};
			};
		};

		cpu7-thermal {
			polling-delay-passive = <100>;
			polling-delay = <0>;
			thermal-sensors = <&tsens 6>;

			trips {
				cpu7_alert0: trip-point0 {
					temperature = <80000>;
					hysteresis = <2000>;
					type = "passive";
				};

				cpu7_alert1: trip-point1 {
					temperature = <90000>;
					hysteresis = <2000>;
					type = "passive";
				};

				cpu7_alert2: trip-point2 {
					temperature = <100000>;
					hysteresis = <2000>;
					type = "passive";
				};

				cpu7-crit {
					temperature = <110000>;
					hysteresis = <2000>;
					type = "critical";
				};
			};

			cooling-maps {
				map0 {
					trip = <&cpu7_alert0>;
					cooling-device = <&cpu4 THERMAL_NO_LIMIT 3>,
						 <&cpu5 THERMAL_NO_LIMIT 3>,
						 <&cpu6 THERMAL_NO_LIMIT 3>,
						 <&cpu7 THERMAL_NO_LIMIT 3>;
				};

				map1 {
					trip = <&cpu7_alert1>;
					cooling-device = <&cpu4 4 6>,
						 <&cpu5 4 6>,
						 <&cpu6 4 6>,
						 <&cpu7 4 6>;
				};

				map2 {
					trip = <&cpu7_alert2>;
					cooling-device = <&cpu4 7 THERMAL_NO_LIMIT>,
						 <&cpu5 7 THERMAL_NO_LIMIT>,
						 <&cpu6 7 THERMAL_NO_LIMIT>,
						 <&cpu7 7 THERMAL_NO_LIMIT>;
				};
			};
		};
	};
};

/*
 * Audio: the ADSP plays through QUAT MI2S (SD0) into the NXP TFA9890 speaker
 * amplifier on BLSP2 I2C5 (stock: qcom,msm-mi2s-rx-lines = <1>).
 */
/ {
	sound {
		compatible = "qcom,msm8994-sndcard";
		model = "OnePlus2";

		audio-routing = "AMIC2", "MIC BIAS2",
				"AMIC3", "MIC BIAS3",
				"AMIC4", "MIC BIAS1";

		reg = <0x0 0xfe037000 0x0 0x4>;
		reg-names = "lpaif_quat_mode_muxsel";

		pinctrl-0 = <&quat_mi2s_rx_default>;
		pinctrl-names = "default";

		mm1-dai-link {
			link-name = "MultiMedia1";

			cpu {
				sound-dai = <&q6asmdai MSM_FRONTEND_DAI_MULTIMEDIA1>;
			};
		};

		mm2-dai-link {
			link-name = "MultiMedia2";

			cpu {
				sound-dai = <&q6asmdai MSM_FRONTEND_DAI_MULTIMEDIA2>;
			};
		};

		speaker-dai-link {
			link-name = "Speaker";

			cpu {
				sound-dai = <&q6afedai QUATERNARY_MI2S_RX>;
			};

			platform {
				sound-dai = <&q6routing>;
			};

			codec {
				sound-dai = <&speaker_amp>;
			};
		};

		headphones-dai-link {
			link-name = "Headphones";

			cpu {
				sound-dai = <&q6afedai SLIMBUS_0_RX>;
			};

			platform {
				sound-dai = <&q6routing>;
			};

			codec {
				sound-dai = <&wcd9330 0>;
			};
		};

		microphones-dai-link {
			link-name = "Microphones";

			cpu {
				sound-dai = <&q6afedai SLIMBUS_0_TX>;
			};

			platform {
				sound-dai = <&q6routing>;
			};

			codec {
				sound-dai = <&wcd9330 1>;
			};
		};
	};
};

/* loaded where the stock PIL puts it; the image is relocatable */
&adsp_pil {
	memory-region = <&peripheral_region>;
	firmware-name = "qcom/msm8994/oneplus/oneplus2/adsp.mbn";
};

&blsp2_i2c5 {
	/* stock runs this bus at 100 kHz */
	clock-frequency = <100000>;
	status = "okay";

	speaker_amp: audio-amplifier@36 {
		compatible = "nxp,tfa9890";
		reg = <0x36>;
		reset-gpios = <&tlmm 106 GPIO_ACTIVE_HIGH>;
		vddd-supply = <&vreg_s4a_1p8>;
		sound-name-prefix = "Speaker";
		#sound-dai-cells = <0>;
	};
};

&q6afedai {
	dai@22 {
		qcom,sd-lines = <0>;
	};
};

&q6asmdai {
	memory-region = <&audio_mem>;
};

&tlmm {
	quat_mi2s_rx_default: quat-mi2s-rx-default-state {
		pins = "gpio58", "gpio59", "gpio60";
		function = "qua_mi2s";
		drive-strength = <8>;
		bias-disable;
	};
};

/* The WCD9330 codec on SLIMbus: headset jack, earpiece and microphones */
&pm8994_gpios {
	wcd_mclk_default: wcd-mclk-default-state {
		pins = "gpio15";
		function = PMIC_GPIO_FUNC_FUNC1;
		power-source = <PM8994_GPIO_S4>;
		qcom,drive-strength = <PMIC_GPIO_STRENGTH_LOW>;
		bias-disable;
		input-disable;
		output-low;
	};
};

&slim {
	status = "okay";

	slim@1 {
		reg = <1>;
		#address-cells = <2>;
		#size-cells = <0>;

		wcd9330_ifd: ifd@0,0 {
			compatible = "slim217,130";
			reg = <0 0>;
		};

		wcd9330: codec@1,0 {
			compatible = "slim217,130";
			reg = <1 0>;
			slim-ifc-dev = <&wcd9330_ifd>;

			clocks = <&rpmcc RPM_SMD_DIV_CLK1>;
			clock-names = "mclk";
			interrupts-extended = <&tlmm 72 IRQ_TYPE_LEVEL_HIGH>;
			reset-gpios = <&tlmm 68 GPIO_ACTIVE_LOW>;

			pinctrl-0 = <&wcd_mclk_default>, <&wcd_intr_default>,
				    <&wcd_reset_default>;
			pinctrl-names = "default";

			vdd-buck-supply = <&vreg_s5a_2p15>;
			vdd-tx-h-supply = <&vreg_s4a_1p8>;
			vdd-rx-h-supply = <&vreg_s4a_1p8>;
			vdd-px-supply = <&vreg_s4a_1p8>;
			vdd-a-1p2v-supply = <&vreg_l11a_1p2>;
			vdd-cx1-supply = <&vreg_l11a_1p2>;
			vdd-cx2-supply = <&vreg_l11a_1p2>;

			qcom,mbhc-insert-detect-inverted;
			qcom,hph-class-ab;
			qcom,micbias1-microvolt = <1800000>;
			qcom,micbias2-microvolt = <2700000>;
			qcom,micbias3-microvolt = <1800000>;

			#sound-dai-cells = <1>;
		};
	};
};

&tlmm {
	wcd_intr_default: wcd-intr-default-state {
		pins = "gpio72";
		function = "gpio";
		drive-strength = <2>;
		bias-pull-down;
	};

	wcd_reset_default: wcd-reset-default-state {
		pins = "gpio68";
		function = "gpio";
		drive-strength = <2>;
		bias-disable;
	};
};

/ {
	divclk4: divclk4 {
		compatible = "fixed-clock";
		#clock-cells = <0>;
		clock-frequency = <32768>;
		clock-output-names = "divclk4";
		pinctrl-names = "default";
		pinctrl-0 = <&divclk4_default>;
	};

	vreg_wlan_bt_3p3: wlan-bt-3p3-regulator {
		compatible = "regulator-fixed";
		regulator-name = "wlan_bt_3p3";
		regulator-min-microvolt = <3300000>;
		regulator-max-microvolt = <3300000>;
		gpio = <&pm8994_gpios 9 GPIO_ACTIVE_HIGH>;
		enable-active-high;
		startup-delay-us = <4000>;
		regulator-always-on;
		vin-supply = <&vph_pwr>;
		pinctrl-names = "default";
		pinctrl-0 = <&wlan_bt_3p3_en_default>;
	};

	vreg_wlan_en: wlan-en-regulator {
		compatible = "regulator-fixed";
		regulator-name = "wlan_en";
		regulator-min-microvolt = <3300000>;
		regulator-max-microvolt = <3300000>;
		gpio = <&tlmm 113 GPIO_ACTIVE_HIGH>;
		enable-active-high;
		startup-delay-us = <70000>;
		vin-supply = <&vreg_wlan_bt_3p3>;
		pinctrl-names = "default";
		pinctrl-0 = <&wlan_en_default>;
	};
};

&blsp2_uart2 {
	uart-has-rtscts;
	status = "okay";

	bluetooth {
		compatible = "qcom,qca6174-bt";
		enable-gpios = <&pm8994_gpios 19 GPIO_ACTIVE_HIGH>;
		clocks = <&divclk4>;
	};
};

&pcie1 {
	vdda-supply = <&vreg_l28a_1p0>;
	status = "okay";
};

&pcie1_phy {
	vdda-phy-supply = <&vreg_l28a_1p0>;
	vdda-pll-supply = <&vreg_l12a_1p8>;
	status = "okay";
};

&pcie1_port {
	compatible = "pciclass,0604";
	reset-gpios = <&tlmm 35 GPIO_ACTIVE_LOW>;
	vpcie3v3-supply = <&vreg_wlan_en>;
};

&pm8994_gpios {
	pinctrl-names = "default";
	pinctrl-0 = <&bt_en_default>;

	bt_en_default: bt-en-default-state {
		pins = "gpio19";
		function = PMIC_GPIO_FUNC_NORMAL;
		power-source = <PM8994_GPIO_S4>;
		qcom,drive-strength = <PMIC_GPIO_STRENGTH_LOW>;
		bias-pull-down;
		output-high;
	};

	divclk4_default: divclk4-default-state {
		pins = "gpio18";
		function = PMIC_GPIO_FUNC_FUNC2;
		power-source = <PM8994_GPIO_S4>;
		bias-disable;
	};

	wlan_bt_3p3_en_default: wlan-bt-3p3-en-default-state {
		pins = "gpio9";
		function = PMIC_GPIO_FUNC_NORMAL;
		power-source = <PM8994_GPIO_VPH>;
		qcom,drive-strength = <PMIC_GPIO_STRENGTH_HIGH>;
		bias-disable;
	};
};

&tlmm {
	wlan_en_default: wlan-en-default-state {
		pins = "gpio113";
		function = "gpio";
		drive-strength = <16>;
		bias-pull-down;
	};
};
